# CY8C4xxx register map
File version: 0.1
Registers are 8-bit, read-write, no defined reset value unless marked. A register's access mark holds for its fields unless they carry their own. Offsets are from the block's base; [hi:lo] are bit positions; {n}, {i} and the like mark numbered series.

## SPCIF — Flash Control Interface
Base 0x400E0000
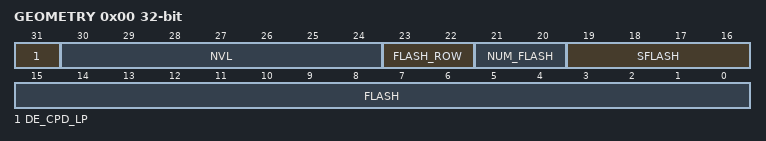
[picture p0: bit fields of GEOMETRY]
0x00 GEOMETRY 32-bit — Flash/NVL geometry information
  [31] DE_CPD_LP — 0: SRAM busy wait loop has not been copied.?1: Busy wait loop has been written into SRAM.
  [30:24] NVL ro — NVL Size in bytes
  [23:22] FLASH_ROW ro — Flash row size in 128B units
  [21:20] NUM_FLASH ro — Number of flash arrays
  [19:16] SFLASH ro — Supervisory Flash Size in 256B segments
  [15:0] FLASH ro — Flash size in 256B segments
0x1C NVL_WR_DATA 32-bit — NVL Write Data Register
  [7:0] DATA — Data to be written to NVL array

## UDB — Programmable Digital Subsystem
Base 0x400F0000
0x8000 INT_CFG 32-bit — UDB Subsystem Interrupt Configuration
  [31:0] INT_MODE_CFG — Interrupt Mode; bit position corresponds to interrupt
    0=LEVEL; 1=PULSE

## UDB_W8 — UDB Working Registers 8-bit mode (1 UDB at a time)
Base 0x400F0000; alternate view of UDB
{0x0+i} A0_{i:02} (i=0..3) — Accumulator 0
  [7:0] A0
{0x10+i} A1_{i:02} (i=0..3) — Accumulator 1
  [7:0] A1
{0x20+i} D0_{i:02} (i=0..3) — Data 0
  [7:0] D0
{0x30+i} D1_{i:02} (i=0..3) — Data 1
  [7:0] D1
{0x40+i} F0_{i:02} (i=0..3) — FIFO 0
  [7:0] F0 — Fifo 0
{0x50+i} F1_{i:02} (i=0..3) — FIFO 1
  [7:0] F1 — Fifo 1
{0x60+i} ST_{i:02} (i=0..3) — Status Register
  [7:0] ST ro — Status register
{0x70+i} CTL_{i:02} (i=0..3) — Control Register
  [7:0] CTL — Control register
{0x80+i} MSK_{i:02} (i=0..3) — Interrupt Mask
  [6:0] MSK — Interrupt Mask Register
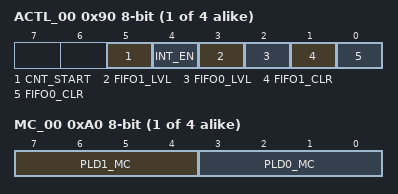
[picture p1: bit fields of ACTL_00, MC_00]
{0x90+i} ACTL_{i:02} (i=0..3) — Auxiliary Control
  [5] CNT_START — Control Register Counter Enable
    0=DISABLE; 1=ENABLE
  [4] INT_EN — enable interrupt
    0=DISABLE; 1=ENABLE
  [3] FIFO1_LVL — FIFO fill status level control
    0=NORMAL; 1=MID
  [2] FIFO0_LVL — FIFO fill status level control
    0=NORMAL; 1=MID
  [1] FIFO1_CLR — FIFO clear
    0=NORMAL; 1=CLEAR
  [0] FIFO0_CLR — FIFO clear
    0=NORMAL; 1=CLEAR
{0xA0+i} MC_{i:02} (i=0..3) — PLD Macrocell reading
  [7:4] PLD1_MC ro — Read Macrocell 1
  [3:0] PLD0_MC ro — Read Macrocell 0

## UDB_W16 — UDB Working Registers 16-bit mode (2 consecutive UDB's)
Base 0x400F1000; alternate view of UDB
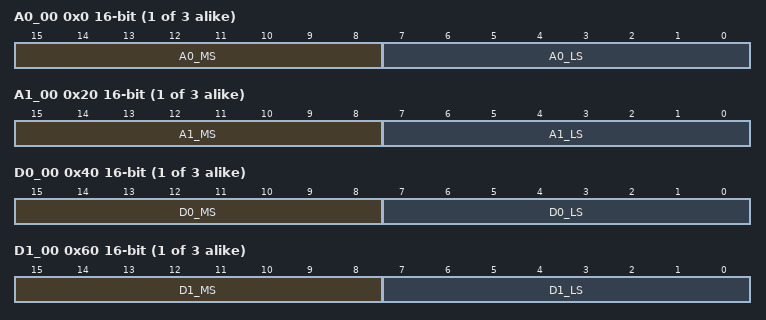
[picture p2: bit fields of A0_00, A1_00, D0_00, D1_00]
{0x0+2i} A0_{i:02} 16-bit (i=0..2) — Accumulator 0
  [15:8] A0_MS — Accumulator 0 for UDB[n+1]
  [7:0] A0_LS — Accumulator 0 for UDB[n]
{0x20+2i} A1_{i:02} 16-bit (i=0..2) — Accumulator 1
  [15:8] A1_MS — Accumulator 1 for UDB[n+1]
  [7:0] A1_LS — Accumulator 1 for UDB[n]
{0x40+2i} D0_{i:02} 16-bit (i=0..2) — Data 0
  [15:8] D0_MS — Data 0 for UDB[n+1]
  [7:0] D0_LS — Data 0 for UDB[n]
{0x60+2i} D1_{i:02} 16-bit (i=0..2) — Data 1
  [15:8] D1_MS — Data 1 for UDB[n+1]
  [7:0] D1_LS — Data 1 for UDB[n]
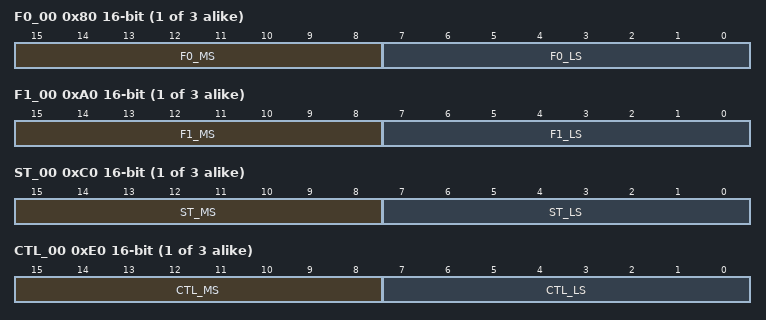
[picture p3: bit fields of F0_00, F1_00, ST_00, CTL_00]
{0x80+2i} F0_{i:02} 16-bit (i=0..2) — FIFO 0
  [15:8] F0_MS — Fifo 0 for UDB[n+1]
  [7:0] F0_LS — Fifo 0 for UDB[n]
{0xA0+2i} F1_{i:02} 16-bit (i=0..2) — FIFO 1
  [15:8] F1_MS — Fifo 1 for UDB[n+1]
  [7:0] F1_LS — Fifo 1 for UDB[n]
{0xC0+2i} ST_{i:02} 16-bit (i=0..2) — Status Register
  [15:8] ST_MS ro — Status register for UDB[n+1]
  [7:0] ST_LS ro — Status register for UDB[n]
{0xE0+2i} CTL_{i:02} 16-bit (i=0..2) — Control Register
  [15:8] CTL_MS — Control register for UDB[n+1]
  [7:0] CTL_LS — Control register for UDB[n]
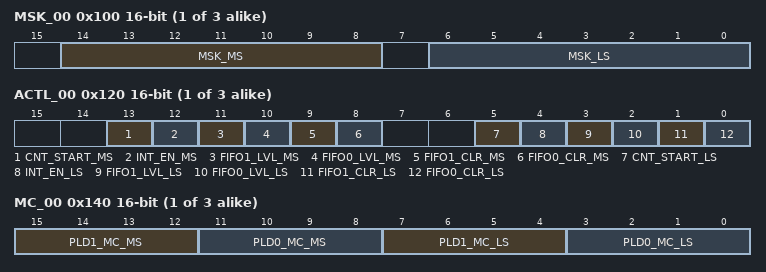
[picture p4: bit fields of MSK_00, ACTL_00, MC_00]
{0x100+2i} MSK_{i:02} 16-bit (i=0..2) — Interrupt Mask
  [14:8] MSK_MS — Interrupt Mask Register
  [6:0] MSK_LS — Interrupt Mask Register
{0x120+2i} ACTL_{i:02} 16-bit (i=0..2) — Auxiliary Control
  [13] CNT_START_MS — Control Register Counter Enable
    0=DISABLE; 1=ENABLE
  [12] INT_EN_MS — enable interrupt
    0=DISABLE; 1=ENABLE
  [11] FIFO1_LVL_MS — FIFO fill status level control
    0=NORMAL; 1=MID
  [10] FIFO0_LVL_MS — FIFO fill status level control
    0=NORMAL; 1=MID
  [9] FIFO1_CLR_MS — FIFO clear
    0=NORMAL; 1=CLEAR
  [8] FIFO0_CLR_MS — FIFO clear
    0=NORMAL; 1=CLEAR
  [5] CNT_START_LS — Control Register Counter Enable
    0=DISABLE; 1=ENABLE
  [4] INT_EN_LS — enable interrupt
    0=DISABLE; 1=ENABLE
  [3] FIFO1_LVL_LS — FIFO fill status level control
    0=NORMAL; 1=MID
  [2] FIFO0_LVL_LS — FIFO fill status level control
    0=NORMAL; 1=MID
  [1] FIFO1_CLR_LS — FIFO clear
    0=NORMAL; 1=CLEAR
  [0] FIFO0_CLR_LS — FIFO clear
    0=NORMAL; 1=CLEAR
{0x140+2i} MC_{i:02} 16-bit (i=0..2) — PLD Macrocell reading
  [15:12] PLD1_MC_MS ro — Read Macrocell 1 for UDB[n+1]
  [11:8] PLD0_MC_MS ro — Read Macrocell 0 for UDB[n+1]
  [7:4] PLD1_MC_LS ro — Read Macrocell 1 for UDB[n]
  [3:0] PLD0_MC_LS ro — Read Macrocell 0 for UDB[n]
